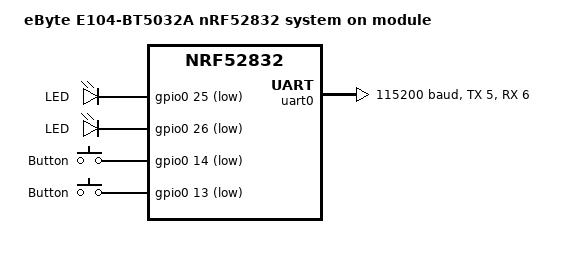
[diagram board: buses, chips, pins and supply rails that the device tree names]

/dts-v1/;
#include <nordic/nrf52832_qfaa.dtsi>

/ {
	model = "eByte E104-BT5032A nRF52832 system on module";

	compatible = "ebyte,nrf52832";

	chosen {
		zephyr,console = &uart0;
		zephyr,shell-uart = &uart0;
		zephyr,uart-mcumgr = &uart0;
		zephyr,bt-mon-uart = &uart0;
		zephyr,bt-c2h-uart = &uart0;
		zephyr,sram = &sram0;
		zephyr,flash = &flash0;
		zephyr,code-partition = &slot0_partition;
	};

	/* These aliases are provided for compatibility with samples */
	aliases {
		led0 = &led0;
		led1 = &led1;
		sw0 = &button0;
		sw1 = &button1;
	};

	leds {
		compatible = "gpio-leds";
		led0: led_0 {
			gpios = <&gpio0 25 GPIO_ACTIVE_LOW>;
			label = "LED";
		};
		led1: led_1 {
			gpios = <&gpio0 26 GPIO_ACTIVE_LOW>;
			label = "LED";
		};
	};

	buttons {
		compatible = "gpio-keys";
		button0: button_0 {
			gpios = <&gpio0 14 (GPIO_PULL_UP | GPIO_ACTIVE_LOW)>;
			label = "Button";
		};
		button1: button_1 {
			/* gpio flags need validation */
			gpios = <&gpio0 13 (GPIO_PULL_UP | GPIO_ACTIVE_LOW)>;
			label = "Button";
		};
	};
};

&gpiote {
	status = "okay";
};

&gpio0 {
	status = "okay";
};

&uart0 {
	compatible = "nordic,nrf-uart";
	current-speed = <115200>;
	status = "okay";
	tx-pin = <5>;
	rx-pin = <6>;
	// rts-pin = <7>;
	// cts-pin = <9>;`
};

&flash0 {
	/*
	 * For more information, see:
	 * http://docs.zephyrproject.org/latest/guides/dts/index.html#flash-partitions
	 */
	partitions {
		compatible = "fixed-partitions";
		#address-cells = <1>;
		#size-cells = <1>;

		boot_partition: partition@0 {
			label = "mcuboot";
			reg = <0x00000000 0xc000>;
		};
		slot0_partition: partition@c000 {
			label = "image-0";
			reg = <0x0000c000 0x32000>;
		};
		slot1_partition: partition@3e000 {
			label = "image-1";
			reg = <0x0003e000 0x32000>;
		};
		scratch_partition: partition@70000 {
			label = "image-scratch";
			reg = <0x00070000 0xa000>;
		};
		storage_partition: partition@7a000 {
			label = "storage";
			reg = <0x0007a000 0x00006000>;
		};
	};
};
